# MCXA156 register map
Vendor: nxp.com; File version: 1.0
CPU: CM33 r2p0, little endian, no MPU, FPU, VTOR, 3 interrupt priority bits
Registers are 32-bit, read-write, reset 0x0 unless marked. A register's access mark holds for its fields unless they carry their own. Offsets are from the block's base; [hi:lo] are bit positions; {n}, {i} and the like mark numbered series.

## QDC0 — Quadrature_Decoder
Base 0x400A7000
Same registers: QDC1 0x400A8000
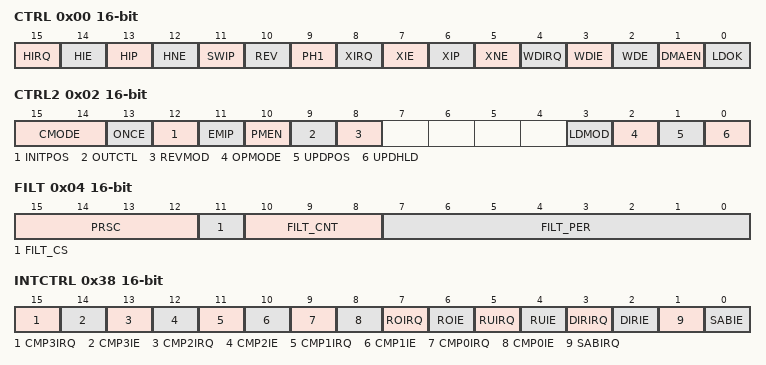
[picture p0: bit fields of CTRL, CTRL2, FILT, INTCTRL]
0x00 CTRL 16-bit — Control Register
  [15] HIRQ write-1-clears — HOME/ENABLE Signal Transition Interrupt Request
    0=No transition on the HOME/ENABLE signal has occurred; 1=A transition on the HOME/ENABLE signal has occurred
  [14] HIE — HOME/ENABLE Interrupt Enable
    0=Disabled; 1=Enabled
  [13] HIP — Enable HOME to Initialize Position Counter UPOS/LPOS
    0=No action; 1=HOME signal initializes the position counter
  [12] HNE — Use Negative Edge of HOME/ENABLE Input
    0=When CTRL[OPMODE] = 0,use HOME positive edge to trigger initialization of position counters. When CTRL[OPMODE] = 1,use ENABLE high level to enable POS/POSD/WDG/REV counters; 1=When CTRL[OPMODE] = 0,use HOME negative edge to trigger initialization of position counters. When CTRL[OPMODE] = 1,use ENABLE low level to enable POS/POSD/WDG/REV counters
  [11] SWIP — Software-Triggered Initialization of Position Counters UPOS and LPOS
    0=No action; 1=Initialize position counter
  [10] REV — Enable Reverse Direction Counting
    0=Count normally and the position counter initialization uses upper/lower initialization register UINIT/LINIT; 1=Count in the reverse direction and the position counter initialization uses upper/lower modulus register UMOD/LMOD
  [9] PH1 — Enable Single Phase Mode
    0=Standard quadrature decoder, where PHASEA and PHASEB represent a two-phase quadrature signal; 1=Single phase mode, bypass the quadrature decoder, refer to CTRL2[CMODE] description
  [8] XIRQ write-1-clears — INDEX/PRESET Pulse Interrupt Request
    0=INDEX/PRESET pulse has not occurred; 1=INDEX/PRESET pulse has occurred
  [7] XIE — INDEX/PRESET Pulse Interrupt Enable
    0=Disabled; 1=Enabled
  [6] XIP — INDEX Triggered Initialization of Position Counters UPOS and LPOS
    0=INDEX pulse does not initialize the position counter; 1=INDEX pulse initializes the position counter
  [5] XNE — Select Positive/Negative Edge of INDEX/PRESET Pulse
    0=Use positive edge of INDEX/PRESET pulse; 1=Use negative edge of INDEX/PRESET pulse
  [4] WDIRQ write-1-clears — Watchdog Timeout Interrupt Request
    0=No Watchdog timeout interrupt has occurred; 1=Watchdog timeout interrupt has occurred
  [3] WDIE — Watchdog Timeout Interrupt Enable
    0=Disabled; 1=Enabled
  [2] WDE — Watchdog Enable
    0=Disabled; 1=Enabled
  [1] DMAEN — DMA Enable
    0=DMA is disabled; 1=DMA is enabled. DMA request asserts automatically when the values in the outer-set of buffered compare registers (UCOMP0/LCOMP0;UCOMP1/LCOMP1;UCOMP2/LCOMP2;UCOMP3/LCOMP3), initial registers(UINIT/LINIT) and modulus registers (UMOD/LMOD) are loaded into the inner-set of buffer and then LDOK is cleared automatically. After the completion of this DMA transfer, LDOK is set automatically, it ensures outer-set values can be loaded into inner-set which in turn triggers DMA again.
  [0] LDOK — Load Okay
    0=No loading action taken. Users can write new values to buffered registers (writing into outer-set of these buffered registers); 1=Outer-set values are ready to be loaded into inner-set and take effect. The loading time point depends on CTRL2[LDMOD].
0x02 CTRL2 16-bit — Control 2 Register
  [15:14] CMODE — Counting Mode
  [13] ONCE — Count Once
    0=Position counter counts repeatedly; 1=Position counter counts until roll-over or roll-under, then stop
  [12] INITPOS — Initial Position Register
    0=Don't initialize position counter on rising edge of TRIGGER; 1=Initialize position counter on rising edge of TRIGGER
  [11] EMIP — Enables/disables the position counter to be initialized by Index Event Edge Mark
    0=disables the position counter to be initialized by Index Event Edge Mark; 1=enables the position counter to be initialized by Index Event Edge Mark
  [10] PMEN — Period measurement function enable
    0=Period measurement functions are not used. POSD is loaded to POSDH and then cleared whenever POSD, UPOS, LPOS or REV is read.; 1=Period measurement functions are used. POSD is loaded into POSDH and then cleared only when POSD is read.
  [9] OUTCTL — Output Control
    0=POS_MATCH[x](x range is 0-3) is asserted when the Position Counter is equal to according compare value (UCOMPx/LCOMPx)(x range is 0-3), and de-asserted when the Position Counter not equal to the compare value (UCOMPx/LCOMPx)(x range is 0-3); 1=All POS_MATCH[x](x range is 0-3) are asserted a pulse, when the UPOS, LPOS, REV, or POSD registers are read
  [8] REVMOD — Revolution Counter Modulus Enable
    0=Use INDEX pulse to increment/decrement revolution counter (REV); 1=Use modulus counting roll-over/under to increment/decrement revolution counter (REV)
  [3] LDMOD — Buffered Register Load (Update) Mode Select
    0=Buffered registers are loaded and take effect immediately upon CTRL[LDOK] is set; 1=Buffered registers are loaded and take effect at the next roll-over or roll-under if CTRL[LDOK] is set
  [2] OPMODE — Operation Mode Select
    0=Decode Mode: Input nodes INDEX/PRESET and HOME/ENABLE are assigned to function of INDEX and HOME; 1=Count Mode: Input nodes INDEX/PRESET and HOME/ENABLE are assigned to functions of PRESET and ENABLE. In this mode: (1)only when ENABLE=1, all counters (position/position difference/revolution/watchdog) can run, when ENABLE=0, all counters (position/position difference/revolution/watchdog) can't run. (2) the rising edge of PRESET input can initialize position/revolution/watchdog counters (position counter initialization also need referring to bit CTRL[REV]).
  [1] UPDPOS — Update Position Registers
  [0] UPDHLD — Update Hold Registers
0x04 FILT 16-bit — Input Filter Register
  [15:12] PRSC — Prescaler
  [11] FILT_CS — Filter Clock Source selection
    0=Peripheral Clock; 1=Prescaled peripheral clock by PRSC
  [10:8] FILT_CNT — Input Filter Sample Count
  [7:0] FILT_PER — Input Filter Sample Period
0x06 LASTEDGE 16-bit ro reset 0xFFFF — Last Edge Time Register
  [15:0] LASTEDGE — Last Edge Time Counter
0x08 POSDPER 16-bit ro reset 0xFFFF — Position Difference Period Counter Register
  [15:0] POSDPER — Position difference period
0x0A POSDPERBFR 16-bit ro reset 0xFFFF — Position Difference Period Buffer Register
  [15:0] POSDPERBFR — Position difference period buffer
0x0C UPOS 16-bit — Upper Position Counter Register
  [15:0] POS
0x0E LPOS 16-bit — Lower Position Counter Register
  [15:0] POS
0x10 POSD 16-bit — Position Difference Counter Register
0x12 POSDH 16-bit ro — Position Difference Hold Register
0x14 UPOSH 16-bit ro — Upper Position Hold Register
  [15:0] POSH
0x16 LPOSH 16-bit ro — Lower Position Hold Register
  [15:0] LPOSH — POSH
0x18 LASTEDGEH 16-bit ro reset 0xFFFF — Last Edge Time Hold Register
  [15:0] LASTEDGEH — Last Edge Time Hold
0x1A POSDPERH 16-bit ro reset 0xFFFF — Position Difference Period Hold Register
  [15:0] POSDPERH — Position difference period hold
0x1C REVH 16-bit ro — Revolution Hold Register
0x1E REV 16-bit — Revolution Counter Register
0x20 UINIT 16-bit — Upper Initialization Register
  [15:0] INIT
0x22 LINIT 16-bit — Lower Initialization Register
  [15:0] INIT
0x24 UMOD 16-bit — Upper Modulus Register
  [15:0] MOD
0x26 LMOD 16-bit — Lower Modulus Register
  [15:0] MOD
0x28 UCOMP0 16-bit reset 0x8000 — Upper Position Compare Register 0
0x2A LCOMP0 16-bit — Lower Position Compare Register 0
{0x28+4i} UCOMP{i} 16-bit wo reset 0x8000 (UCOMP{i}_UPOSH{i} view) (i=1..3) — Upper Position Compare {i}
0x2C UPOSH1 16-bit ro (UCOMP1_UPOSH1 view) — Upper Position Holder Register 1
{0x2A+4i} LCOMP{i} 16-bit wo (LCOMP{i}_LPOSH{i} view) (i=1..3) — Lower Position Compare {i}
{0x2A+4i} LPOSH{i} 16-bit ro (LCOMP{i}_LPOSH{i} view) (i=1..3) — Lower Position Holder Register {i}
0x30 UPOSH2 16-bit ro (UCOMP2_UPOSH2 view) — Upper Position Holder Register 3
0x34 UPOSH3 16-bit ro (UCOMP3_UPOSH3 view) — Upper Position Holder Register 3
0x38 INTCTRL 16-bit — Interrupt Control Register
  [15] CMP3IRQ write-1-clears — Compare3 Interrupt Request
    0=No match has occurred (the position counter does not match the COMP3 value); 1=COMP3 match has occurred (the position counter matches the COMP3 value)
  [14] CMP3IE — Compare3 Interrupt Enable
    0=Disabled; 1=Enabled
  [13] CMP2IRQ write-1-clears — Compare2 Interrupt Request
    0=No match has occurred (the position counter does not match the COMP2 value); 1=COMP2 match has occurred (the position counter matches the COMP2 value)
  [12] CMP2IE — Compare2 Interrupt Enable
    0=Disabled; 1=Enabled
  [11] CMP1IRQ write-1-clears — Compare1 Interrupt Request
    0=No match has occurred (the position counter does not match the COMP1 value); 1=COMP1 match has occurred (the position counter matches the COMP1 value)
  [10] CMP1IE — Compare1 Interrupt Enable
    0=Disabled; 1=Enabled
  [9] CMP0IRQ write-1-clears — Compare 0 Interrupt Request
    0=No match has occurred (the position counter does not match the COMP0 value); 1=COMP match has occurred (the position counter matches the COMP0 value)
  [8] CMP0IE — Compare 0 Interrupt Enable
    0=Disabled; 1=Enabled
  [7] ROIRQ write-1-clears — Roll-over Interrupt Request
    0=No roll-over has occurred; 1=Roll-over has occurred
  [6] ROIE — Roll-over Interrupt Enable
    0=ROIE (Disabled); 1=Enabled
  [5] RUIRQ write-1-clears — Roll-under Interrupt Request
    0=No roll-under has occurred; 1=Roll-under has occurred
  [4] RUIE — Roll-under Interrupt Enable
    0=Disabled; 1=Enabled
  [3] DIRIRQ write-1-clears — Count direction change interrupt
    0=Count direction unchanged; 1=Count direction changed
  [2] DIRIE — Count direction change interrupt enable
    0=Disabled; 1=Enabled
  [1] SABIRQ write-1-clears — Simultaneous PHASEA and PHASEB Change Interrupt Request
    0=No simultaneous change of PHASEA and PHASEB has occurred; 1=A simultaneous change of PHASEA and PHASEB has occurred
  [0] SABIE — Simultaneous PHASEA and PHASEB Change Interrupt Enable
    0=Disabled; 1=Enabled
0x3A WTR 16-bit — Watchdog Timeout Register
  [15:0] WDOG
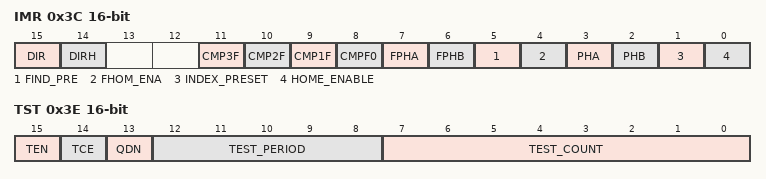
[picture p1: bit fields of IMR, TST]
0x3C IMR 16-bit — Input Monitor Register
  [15] DIR ro — Count Direction Flag Output
    0=Current count was in the down direction; 1=Current count was in the up direction
  [14] DIRH ro — Count Direction Flag Hold
  [11] CMP3F ro — Position Compare3 Flag Output
    0=When the position counter value is less than value of COMP3 register; 1=When the position counter is greater or equal than value of COMP3 register
  [10] CMP2F ro — Position Compare2 Flag Output
    0=When the position counter is less than value of COMP2 register; 1=When the position counter is greater or equal than value of COMP2 register
  [9] CMP1F ro — Position Compare1 Flag Output
    0=When the position counter is less than value of COMP1 register; 1=When the position counter is greater or equal than value of COMP1 register
  [8] CMPF0 ro — Position Compare 0 Flag Output
    0=When the position counter is less than value of COMP0 register; 1=When the position counter is greater or equal than value of COMP0 register
  [7] FPHA — filter operation on PHASEA input
  [6] FPHB — filter operation on PHASEB input
  [5] FIND_PRE — filter operation on INDEX/PRESET input
  [4] FHOM_ENA — filter operation on HOME/ENABLE input
  [3] PHA ro
  [2] PHB ro
  [1] INDEX_PRESET ro
  [0] HOME_ENABLE ro
0x3E TST 16-bit — Test Register
  [15] TEN — Test Mode Enable
    0=Disabled; 1=Enabled
  [14] TCE — Test Counter Enable
    0=Disabled; 1=Enabled
  [13] QDN — Quadrature Decoder Negative Signal
    0=Generates a positive quadrature decoder signal; 1=Generates a negative quadrature decoder signal
  [12:8] TEST_PERIOD
  [7:0] TEST_COUNT
0x50 UVERID 16-bit ro reset 0x1 — Upper VERID
0x52 LVERID 16-bit ro reset 0x1 — Lower VERID
